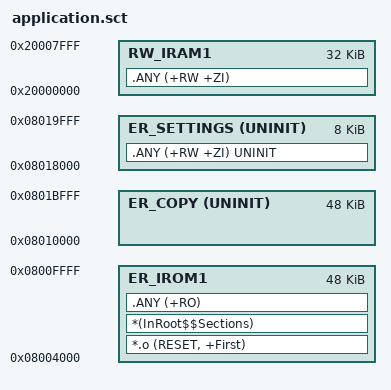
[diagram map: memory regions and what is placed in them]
; ==========================================================
; Scatter File for Main Application (STM32F303CBT6)
; Блок 1: Код (48 КБ), Блок 2: Копия (48 КБ), Блок 3: Настройки (8 КБ)
; ==========================================================

; --- БЛОК 1: Основная прошивка (Исполняемый код) ---
LR_IROM1 0x08004000 0x0000C000  ; 48 КБ Flash
{
    ER_IROM1 0x08004000 0x0000C000
    {
        *.o (RESET, +First)       ; Таблица векторов прерываний основной прошивки
        *(InRoot$$Sections)
        .ANY (+RO)
    }
    
    RW_IRAM1 0x20000000 0x00008000  ; 32 КБ RAM
    {
        .ANY (+RW +ZI)
    }
}

; --- БЛОК 2: Копия прошивки (Только хранение, не исполняется напрямую) ---
; Мы помечаем его как UNINIT, чтобы линкер не пытался инициализировать этот регион при старте
LR_COPY 0x08010000 0x0000C000  ; 48 КБ Flash
{
    ER_COPY 0x08010000 0x0000C000 UNINIT
    {
        ; Оставляем пустым. Прошивка будет писать сюда через функции стирания/записи Flash.
        ; Но наличие этого региона в Scatter-файле гарантирует, что линкер не залезет сюда своим кодом.
    }
}

; --- БЛОК 3: Настройки и метаданные (Хранение данных) ---
LR_SETTINGS 0x08018000 0x00002000  ; 8 КБ Flash
{
    ER_SETTINGS 0x08018000 0x00002000 UNINIT
    {
        ; Сюда линкер будет помещать переменные, помеченные как UNINIT или через секцию .settings
        .ANY (+RW +ZI) UNINIT
    }
}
